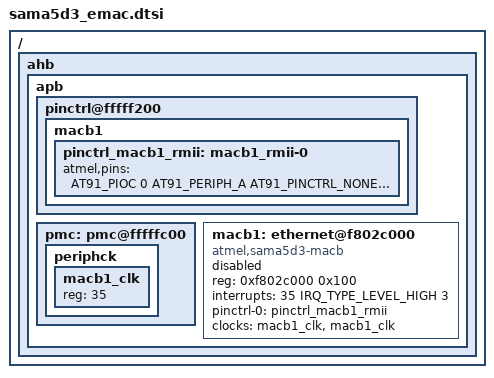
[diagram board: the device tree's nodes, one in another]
// SPDX-License-Identifier: GPL-2.0-only
/*
 * sama5d3_emac.dtsi - Device Tree Include file for SAMA5D3 SoC with
 * Ethernet.
 *
 * Copyright (C) 2013 Boris BREZILLON <b.brezillon@overkiz.com>
 */

#include <dt-bindings/pinctrl/at91.h>
#include <dt-bindings/interrupt-controller/irq.h>

/ {
	ahb {
		apb {
			pinctrl@fffff200 {
				macb1 {
					pinctrl_macb1_rmii: macb1_rmii-0 {
						atmel,pins =
							<AT91_PIOC 0 AT91_PERIPH_A AT91_PINCTRL_NONE	/* PC0 periph A ETX0, conflicts with TIOA3 */
							 AT91_PIOC 1 AT91_PERIPH_A AT91_PINCTRL_NONE	/* PC1 periph A ETX1, conflicts with TIOB3 */
							 AT91_PIOC 2 AT91_PERIPH_A AT91_PINCTRL_NONE	/* PC2 periph A ERX0, conflicts with TCLK3 */
							 AT91_PIOC 3 AT91_PERIPH_A AT91_PINCTRL_NONE	/* PC3 periph A ERX1, conflicts with TIOA4 */
							 AT91_PIOC 4 AT91_PERIPH_A AT91_PINCTRL_NONE	/* PC4 periph A ETXEN, conflicts with TIOB4 */
							 AT91_PIOC 5 AT91_PERIPH_A AT91_PINCTRL_NONE	/* PC5 periph A ECRSDV,conflicts with TCLK4 */
							 AT91_PIOC 6 AT91_PERIPH_A AT91_PINCTRL_NONE	/* PC6 periph A ERXER, conflicts with TIOA5 */
							 AT91_PIOC 7 AT91_PERIPH_A AT91_PINCTRL_NONE	/* PC7 periph A EREFCK, conflicts with TIOB5 */
							 AT91_PIOC 8 AT91_PERIPH_A AT91_PINCTRL_NONE	/* PC8 periph A EMDC, conflicts with TCLK5 */
							 AT91_PIOC 9 AT91_PERIPH_A AT91_PINCTRL_NONE>;	/* PC9 periph A EMDIO  */
					};
				};
			};

			pmc: pmc@fffffc00 {
				periphck {
					macb1_clk: macb1_clk {
						#clock-cells = <0>;
						reg = <35>;
					};
				};
			};

			macb1: ethernet@f802c000 {
				compatible = "atmel,sama5d3-macb", "cdns,at91sam9260-macb", "cdns,macb";
				reg = <0xf802c000 0x100>;
				interrupts = <35 IRQ_TYPE_LEVEL_HIGH 3>;
				pinctrl-names = "default";
				pinctrl-0 = <&pinctrl_macb1_rmii>;
				clocks = <&macb1_clk>, <&macb1_clk>;
				clock-names = "hclk", "pclk";
				status = "disabled";
			};
		};
	};
};
